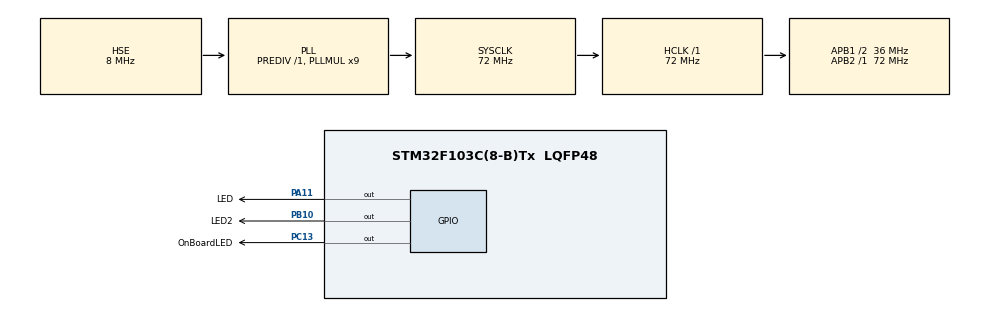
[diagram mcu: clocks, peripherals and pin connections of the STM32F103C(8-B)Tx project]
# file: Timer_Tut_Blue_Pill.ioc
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Dma.Request0=TIM2_UP
Dma.TIM2_UP.0.Direction=DMA_MEMORY_TO_PERIPH
Dma.TIM2_UP.0.Instance=DMA1_Channel2
Dma.TIM2_UP.0.MemDataAlignment=DMA_MDATAALIGN_HALFWORD
Dma.TIM2_UP.0.MemInc=DMA_MINC_ENABLE
Dma.TIM2_UP.0.Mode=DMA_CIRCULAR
Dma.TIM2_UP.0.PeriphDataAlignment=DMA_PDATAALIGN_HALFWORD
Dma.TIM2_UP.0.PeriphInc=DMA_PINC_DISABLE
Dma.TIM2_UP.0.Priority=DMA_PRIORITY_LOW
Mcu.Family=STM32F1
Mcu.Name=STM32F103C(8-B)Tx
Mcu.Package=LQFP48
NVIC.DMA1_Channel2_IRQn=true\:0\:0\:false\:false\:true\:false\:true\:true
NVIC.PriorityGroup=NVIC_PRIORITYGROUP_4
NVIC.TIM2_IRQn=true\:0\:0\:false\:false\:true\:true\:true\:true
PA11.GPIO_Label=LED
PA11.Signal=GPIO_Output
PA13.Mode=Serial_Wire
PA13.Signal=SYS_JTMS-SWDIO
PA14.Mode=Serial_Wire
PA14.Signal=SYS_JTCK-SWCLK
PB10.GPIO_Label=LED2
PB10.Signal=GPIO_Output
PC13-TAMPER-RTC.GPIO_Label=OnBoardLED
PC13-TAMPER-RTC.Signal=GPIO_Output
PD0-OSC_IN.Mode=HSE-External-Oscillator
PD0-OSC_IN.Signal=RCC_OSC_IN
PD1-OSC_OUT.Mode=HSE-External-Oscillator
PD1-OSC_OUT.Signal=RCC_OSC_OUT
ProjectManager.HeapSize=0x200
ProjectManager.StackSize=0x400
ProjectManager.TargetToolchain=STM32CubeIDE
RCC.AHBFreq_Value=72000000
RCC.APB1CLKDivider=RCC_HCLK_DIV2
RCC.APB1Freq_Value=36000000
RCC.APB1TimFreq_Value=72000000
RCC.APB2Freq_Value=72000000
RCC.APB2TimFreq_Value=72000000
RCC.HCLKFreq_Value=72000000
RCC.PLLMUL=RCC_PLL_MUL9
RCC.PLLSourceVirtual=RCC_PLLSOURCE_HSE
RCC.SYSCLKFreq_VALUE=72000000
RCC.SYSCLKSource=RCC_SYSCLKSOURCE_PLLCLK
RCC.USBFreq_Value=72000000
TIM2.AutoReloadPreload=TIM_AUTORELOAD_PRELOAD_ENABLE
TIM2.Period=1000
TIM2.Prescaler=36000
TIM2.TIM_MasterOutputTrigger=TIM_TRGO_RESET
VP_TIM2_VS_ClockSourceINT.Mode=Internal
board=custom

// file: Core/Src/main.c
/* USER CODE BEGIN Header */
/**
  ******************************************************************************
  * @file           : main.c
  * @brief          : Main program body
  ******************************************************************************
  * @attention
  *
  * Copyright (c) 2023 STMicroelectronics.
  * All rights reserved.
  *
  * This software is licensed under terms that can be found in the LICENSE file
  * in the root directory of this software component.
  * If no LICENSE file comes with this software, it is provided AS-IS.
  *
  ******************************************************************************
  */
/* USER CODE END Header */
#include "main.h"

 TIM_HandleTypeDef htim2;
DMA_HandleTypeDef hdma_tim2_up;

void SystemClock_Config(void);
static void MX_GPIO_Init(void);
static void MX_DMA_Init(void);
static void MX_TIM2_Init(void);

int main(void)
{

  /* MCU Configuration--------------------------------------------------------*/

  /* Reset of all peripherals, Initializes the Flash interface and the Systick. */
  HAL_Init();

  /* Configure the system clock */
  SystemClock_Config();

  /* Initialize all configured peripherals */
  MX_GPIO_Init();
  MX_DMA_Init();
  MX_TIM2_Init();
  /* USER CODE BEGIN 2 */

  //// <-- using Interrupt --> ////
  HAL_TIM_Base_Start_IT(&htim2);

  //// <-- using DMA --> ////
  hdma_tim2_up.Instance = DMA1_Channel2;
  hdma_tim2_up.Init.Direction = DMA_MEMORY_TO_PERIPH;
  hdma_tim2_up.Init.PeriphInc = DMA_PINC_DISABLE;
  hdma_tim2_up.Init.MemInc = DMA_MINC_ENABLE;
  hdma_tim2_up.Init.PeriphDataAlignment = DMA_PDATAALIGN_BYTE;
  hdma_tim2_up.Init.MemDataAlignment = DMA_MDATAALIGN_BYTE;
  hdma_tim2_up.Init.Mode = DMA_CIRCULAR;
  hdma_tim2_up.Init.Priority = DMA_PRIORITY_LOW;
  HAL_DMA_Init( &hdma_tim2_up );

  uint8_t data[] = {0xFF, 0x0}; // all

  /* Enable the DMA channel */
  HAL_DMA_Start( &hdma_tim2_up, (uint32_t)data, (uint32_t)&LED_GPIO_Port->ODR, 2 );

  /* Enable the TIM Update DMA request */
  __HAL_TIM_ENABLE_DMA( &htim2, TIM_DMA_UPDATE );

  /* USER CODE END 2 */

  /* Infinite loop */
  /* USER CODE BEGIN WHILE */
  while (1)
  {
	  //// <-- using Polling --> ////
	  if(__HAL_TIM_GET_COUNTER(&htim2) >= 500 ){	// max counter value is 1000
		  HAL_GPIO_WritePin(LED2_GPIO_Port, LED2_Pin, GPIO_PIN_SET);
	  }else
		  HAL_GPIO_WritePin(LED2_GPIO_Port, LED2_Pin, GPIO_PIN_RESET);

    /* USER CODE END WHILE */

  }
}

void SystemClock_Config(void)
{
  RCC_OscInitTypeDef RCC_OscInitStruct = {0};
  RCC_ClkInitTypeDef RCC_ClkInitStruct = {0};

  /** Initializes the RCC Oscillators according to the specified parameters
  * in the RCC_OscInitTypeDef structure.
  */
  RCC_OscInitStruct.OscillatorType = RCC_OSCILLATORTYPE_HSE;
  RCC_OscInitStruct.HSEState = RCC_HSE_ON;
  RCC_OscInitStruct.HSEPredivValue = RCC_HSE_PREDIV_DIV1;
  RCC_OscInitStruct.HSIState = RCC_HSI_ON;
  RCC_OscInitStruct.PLL.PLLState = RCC_PLL_ON;
  RCC_OscInitStruct.PLL.PLLSource = RCC_PLLSOURCE_HSE;
  RCC_OscInitStruct.PLL.PLLMUL = RCC_PLL_MUL9;
  if (HAL_RCC_OscConfig(&RCC_OscInitStruct) != HAL_OK)
  {
    Error_Handler();
  }

  /** Initializes the CPU, AHB and APB buses clocks
  */
  RCC_ClkInitStruct.ClockType = RCC_CLOCKTYPE_HCLK|RCC_CLOCKTYPE_SYSCLK
                              |RCC_CLOCKTYPE_PCLK1|RCC_CLOCKTYPE_PCLK2;
  RCC_ClkInitStruct.SYSCLKSource = RCC_SYSCLKSOURCE_PLLCLK;
  RCC_ClkInitStruct.AHBCLKDivider = RCC_SYSCLK_DIV1;
  RCC_ClkInitStruct.APB1CLKDivider = RCC_HCLK_DIV2;
  RCC_ClkInitStruct.APB2CLKDivider = RCC_HCLK_DIV1;

  if (HAL_RCC_ClockConfig(&RCC_ClkInitStruct, FLASH_LATENCY_2) != HAL_OK)
  {
    Error_Handler();
  }
}

static void MX_TIM2_Init(void)
{

  TIM_ClockConfigTypeDef sClockSourceConfig = {0};
  TIM_MasterConfigTypeDef sMasterConfig = {0};

  htim2.Instance = TIM2;
  htim2.Init.Prescaler = 36000;
  htim2.Init.CounterMode = TIM_COUNTERMODE_UP;
  htim2.Init.Period = 1000;
  htim2.Init.ClockDivision = TIM_CLOCKDIVISION_DIV1;
  htim2.Init.AutoReloadPreload = TIM_AUTORELOAD_PRELOAD_ENABLE;
  if (HAL_TIM_Base_Init(&htim2) != HAL_OK)
  {
    Error_Handler();
  }
  sClockSourceConfig.ClockSource = TIM_CLOCKSOURCE_INTERNAL;
  if (HAL_TIM_ConfigClockSource(&htim2, &sClockSourceConfig) != HAL_OK)
  {
    Error_Handler();
  }
  sMasterConfig.MasterOutputTrigger = TIM_TRGO_RESET;
  sMasterConfig.MasterSlaveMode = TIM_MASTERSLAVEMODE_DISABLE;
  if (HAL_TIMEx_MasterConfigSynchronization(&htim2, &sMasterConfig) != HAL_OK)
  {
    Error_Handler();
  }

}

static void MX_DMA_Init(void)
{

  /* DMA controller clock enable */
  __HAL_RCC_DMA1_CLK_ENABLE();

  /* DMA interrupt init */
  /* DMA1_Channel2_IRQn interrupt configuration */
  HAL_NVIC_SetPriority(DMA1_Channel2_IRQn, 0, 0);
  HAL_NVIC_EnableIRQ(DMA1_Channel2_IRQn);

}

static void MX_GPIO_Init(void)
{
  GPIO_InitTypeDef GPIO_InitStruct = {0};

  /* GPIO Ports Clock Enable */
  __HAL_RCC_GPIOC_CLK_ENABLE();
  __HAL_RCC_GPIOD_CLK_ENABLE();
  __HAL_RCC_GPIOB_CLK_ENABLE();
  __HAL_RCC_GPIOA_CLK_ENABLE();

  /*Configure GPIO pin Output Level */
  HAL_GPIO_WritePin(OnBoardLED_GPIO_Port, OnBoardLED_Pin, GPIO_PIN_RESET);

  /*Configure GPIO pin Output Level */
  HAL_GPIO_WritePin(LED2_GPIO_Port, LED2_Pin, GPIO_PIN_RESET);

  /*Configure GPIO pin Output Level */
  HAL_GPIO_WritePin(LED_GPIO_Port, LED_Pin, GPIO_PIN_RESET);

  /*Configure GPIO pin : OnBoardLED_Pin */
  GPIO_InitStruct.Pin = OnBoardLED_Pin;
  GPIO_InitStruct.Mode = GPIO_MODE_OUTPUT_PP;
  GPIO_InitStruct.Pull = GPIO_NOPULL;
  GPIO_InitStruct.Speed = GPIO_SPEED_FREQ_LOW;
  HAL_GPIO_Init(OnBoardLED_GPIO_Port, &GPIO_InitStruct);

  /*Configure GPIO pin : LED2_Pin */
  GPIO_InitStruct.Pin = LED2_Pin;
  GPIO_InitStruct.Mode = GPIO_MODE_OUTPUT_PP;
  GPIO_InitStruct.Pull = GPIO_NOPULL;
  GPIO_InitStruct.Speed = GPIO_SPEED_FREQ_LOW;
  HAL_GPIO_Init(LED2_GPIO_Port, &GPIO_InitStruct);

  /*Configure GPIO pin : LED_Pin */
  GPIO_InitStruct.Pin = LED_Pin;
  GPIO_InitStruct.Mode = GPIO_MODE_OUTPUT_PP;
  GPIO_InitStruct.Pull = GPIO_NOPULL;
  GPIO_InitStruct.Speed = GPIO_SPEED_FREQ_LOW;
  HAL_GPIO_Init(LED_GPIO_Port, &GPIO_InitStruct);

}

/* USER CODE BEGIN 4 */
void HAL_TIM_PeriodElapsedCallback(TIM_HandleTypeDef* htim)
{
	// This callback is automatically called by the HAL on the UEV event
	if(htim->Instance == TIM2)
		  HAL_GPIO_TogglePin(OnBoardLED_GPIO_Port, OnBoardLED_Pin);
}
/* USER CODE END 4 */

void Error_Handler(void)
{
  __disable_irq();
  while (1)
  {
  }
}
